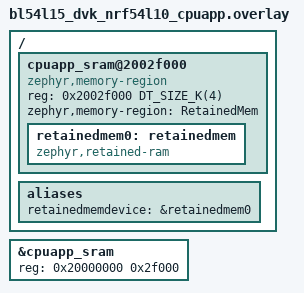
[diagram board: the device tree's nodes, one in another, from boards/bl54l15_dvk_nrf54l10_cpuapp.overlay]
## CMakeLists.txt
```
# SPDX-License-Identifier: Apache-2.0

cmake_minimum_required(VERSION 3.28.0)
find_package(Zephyr REQUIRED HINTS $ENV{ZEPHYR_BASE})
project(nrf_system_off)

target_sources(app PRIVATE src/main.c)
if(CONFIG_APP_USE_RETAINED_MEM)
  target_sources(app PRIVATE src/retained.c)
endif()
```

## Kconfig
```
# Copyright (c) 2021 Nordic Semiconductor ASA
# SPDX-License-Identifier: Apache-2.0

mainmenu "Nordic SYSTEM_OFF demo"

config APP_USE_RETAINED_MEM
	bool "Use state retention in system off using retained_mem driver"
	select RETAINED_MEM

config GPIO_WAKEUP_ENABLE
	bool "Use button to wake up device from system off"
	default y
	help
	  Enable system off wakeup from pressing sw0 button.

config GRTC_WAKEUP_ENABLE
	bool "Use GRTC to wake up device from system off"
	help
	  Enable system off wakeup from GRTC.

config LPCOMP_WAKEUP_ENABLE
	bool "Use COMP to wake up device from system off"
	help
	  Enable system off wakeup from analog comparator.

config SYS_CLOCK_DISABLE
	bool "Power down system clock before system off"
	help
	  System clock and GRTC will be switched off during system off.

source "Kconfig.zephyr"
```

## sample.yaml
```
sample:
  name: Low Power State Sample for nRF5x
common:
  tags: power
tests:
  sample.boards.nrf.system_off:
    integration_platforms:
      - nrf52840dk/nrf52840
    platform_allow:
      - nrf51dk/nrf51822
      - nrf52840dk/nrf52840
      - nrf52dk/nrf52832
      - nrf5340dk/nrf5340/cpuapp
      - nrf54l15dk/nrf54l05/cpuapp
      - nrf54l15dk/nrf54l10/cpuapp
      - nrf54l15dk/nrf54l15/cpuapp
      - nrf54lm20dk/nrf54lm20a/cpuapp
      - nrf54lm20dk/nrf54lm20b/cpuapp
      - nrf7120dk/nrf7120/cpuapp
    harness: console
    harness_config:
      type: multi_line
      ordered: true
      regex:
        - "system off demo"
        - "Retained data not supported"
        - "Entering system off; press sw0 to restart"
  sample.boards.nrf.system_off.retained_mem:
    integration_platforms:
      - nrf52840dk/nrf52840
    platform_allow:
      - nrf52840dk/nrf52840
      - nrf52dk/nrf52832
      - nrf5340dk/nrf5340/cpuapp
      - nrf54l15dk/nrf54l05/cpuapp
      - nrf54l15dk/nrf54l10/cpuapp
      - nrf54l15dk/nrf54l15/cpuapp
      - nrf54lm20dk/nrf54lm20a/cpuapp
      - nrf54lm20dk/nrf54lm20b/cpuapp
      - nrf7120dk/nrf7120/cpuapp
    extra_configs:
      - CONFIG_APP_USE_RETAINED_MEM=y
    harness: console
    harness_config:
      type: multi_line
      ordered: true
      regex:
        - "system off demo"
        - "Retained data: valid"
        - "Boot count: 1"
        - "Off count: 0"
        - "Active Ticks:"
        - "Entering system off; press sw0 to restart"
  sample.boards.nrf.system_off.grtc_off:
    platform_allow:
      - nrf54l15dk/nrf54l05/cpuapp
      - nrf54l15dk/nrf54l10/cpuapp
      - nrf54l15dk/nrf54l15/cpuapp
      - nrf54lm20dk/nrf54lm20a/cpuapp
      - nrf54lm20dk/nrf54lm20b/cpuapp
      - nrf7120dk/nrf7120/cpuapp
    extra_configs:
      - CONFIG_SYS_CLOCK_DISABLE=y
    harness: console
    harness_config:
      type: multi_line
      ordered: true
      regex:
        - "system off demo"
        - "Retained data not supported"
        - "System clock will be disabled"
        - "Entering system off; press sw0 to restart"
  sample.boards.nrf.system_off.retained_mem.grtc_off:
    platform_allow:
      - nrf54l15dk/nrf54l05/cpuapp
      - nrf54l15dk/nrf54l10/cpuapp
      - nrf54l15dk/nrf54l15/cpuapp
      - nrf54lm20dk/nrf54lm20a/cpuapp
      - nrf54lm20dk/nrf54lm20b/cpuapp
      - nrf7120dk/nrf7120/cpuapp
    extra_configs:
      - CONFIG_APP_USE_RETAINED_MEM=y
      - CONFIG_SYS_CLOCK_DISABLE=y
    harness: console
    harness_config:
      type: multi_line
      ordered: true
      regex:
        - "system off demo"
        - "Retained data: valid"
        - "Boot count: 1"
        - "Off count: 0"
        - "Active Ticks:"
        - "System clock will be disabled"
        - "Entering system off; press sw0 to restart"
  sample.boards.nrf.system_off.grtc_wakeup:
    platform_allow:
      - nrf54l15dk/nrf54l05/cpuapp
      - nrf54l15dk/nrf54l10/cpuapp
      - nrf54l15dk/nrf54l15/cpuapp
      - nrf54lm20dk/nrf54lm20a/cpuapp
      - nrf54lm20dk/nrf54lm20b/cpuapp
      - nrf7120dk/nrf7120/cpuapp
    extra_configs:
      - CONFIG_GRTC_WAKEUP_ENABLE=y
      - CONFIG_GPIO_WAKEUP_ENABLE=n
    harness: console
    harness_config:
      type: multi_line
      ordered: true
      regex:
        - "system off demo"
        - "Retained data not supported"
        - "Entering system off; wait 2 seconds to restart"
        - "system off demo"
        - "Retained data not supported"
        - "Entering system off; wait 2 seconds to restart"
        - "system off demo"
        - "Wakeup from System OFF by GRTC."
        - "Retained data not supported"
        - "Entering system off; wait 2 seconds to restart"
  sample.boards.nrf.system_off.retained_mem.grtc_wakeup:
    platform_allow:
      - nrf54l15dk/nrf54l05/cpuapp
      - nrf54l15dk/nrf54l10/cpuapp
      - nrf54l15dk/nrf54l15/cpuapp
      - nrf54lm20dk/nrf54lm20a/cpuapp
      - nrf54lm20dk/nrf54lm20b/cpuapp
      - nrf7120dk/nrf7120/cpuapp
    extra_configs:
      - CONFIG_APP_USE_RETAINED_MEM=y
      - CONFIG_GRTC_WAKEUP_ENABLE=y
      - CONFIG_GPIO_WAKEUP_ENABLE=n
    harness: console
    harness_config:
      type: multi_line
      ordered: true
      regex:
        - "system off demo"
        - "Retained data: valid"
        - "Boot count: 1"
        - "Off count: 0"
        - "Active Ticks:"
        - "Entering system off; wait 2 seconds to restart"
        - "system off demo"
        - "Retained data: valid"
        - "Boot count: 2"
        - "Off count: 1"
        - "Active Ticks:"
        - "Entering system off; wait 2 seconds to restart"
        - "Wakeup from System OFF by GRTC."
  sample.boards.nrf.system_off.lpcomp_wakeup:
    extra_args: DTC_OVERLAY_FILE="boards/nrf54l15dk_nrf54l15_cpuapp_comparator.overlay"
    platform_allow:
      - nrf54l15dk/nrf54l15/cpuapp
    extra_configs:
      - CONFIG_LPCOMP_WAKEUP_ENABLE=y
      - CONFIG_GPIO_WAKEUP_ENABLE=n
      - CONFIG_COMPARATOR=y
    harness: console
    harness_config:
      type: multi_line
      ordered: true
      regex:
        - "system off demo"
        - "Retained data not supported"
        - "Entering system off; change signal level at comparator input to restart"
  sample.boards.nrf.system_off.retained_mem.lpcomp_wakeup:
    extra_args:
      - "DTC_OVERLAY_FILE=
         boards/nrf54l15dk_nrf54l15_cpuapp_comparator.overlay;
         boards/nrf54l15dk_nrf54l15_cpuapp.overlay"
    platform_allow:
      - nrf54l15dk/nrf54l15/cpuapp
    extra_configs:
      - CONFIG_APP_USE_RETAINED_MEM=y
      - CONFIG_GPIO_WAKEUP_ENABLE=n
      - CONFIG_LPCOMP_WAKEUP_ENABLE=y
      - CONFIG_RETAINED_MEM=y
      - CONFIG_COMPARATOR=y
    harness: console
    harness_config:
      type: multi_line
      ordered: true
      regex:
        - "system off demo"
        - "Retained data: valid"
        - "Boot count: 1"
        - "Off count: 0"
        - "Active Ticks:"
        - "Entering system off; change signal level at comparator input to restart"
```

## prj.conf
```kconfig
CONFIG_PM_DEVICE=y
CONFIG_GPIO=y
CONFIG_CRC=y
CONFIG_POWEROFF=y
CONFIG_HWINFO=y
```

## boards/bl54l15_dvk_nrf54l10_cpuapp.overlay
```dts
/*
 * SPDX-License-Identifier: Apache-2.0
 *
 * Copyright (c) 2024 Nordic Semiconductor ASA
 * Copyright (c) 2025 Ezurio LLC
 */

/ {
	cpuapp_sram@2002f000 {
		compatible = "zephyr,memory-region", "mmio-sram";
		reg = <0x2002f000 DT_SIZE_K(4)>;
		zephyr,memory-region = "RetainedMem";
		status = "okay";

		retainedmem0: retainedmem {
			compatible = "zephyr,retained-ram";
			status = "okay";
		};
	};

	aliases {
		retainedmemdevice = &retainedmem0;
	};
};

&cpuapp_sram {
	/* Shrink SRAM size to avoid overlap with retained memory region:
	 * 192 - 4 = 188KB = 0x2f000
	 */
	reg = <0x20000000 0x2f000>;
	ranges = <0x0 0x20000000 0x2f000>;
};
```

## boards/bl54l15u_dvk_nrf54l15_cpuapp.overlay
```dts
/*
 * SPDX-License-Identifier: Apache-2.0
 *
 * Copyright (c) 2024 Nordic Semiconductor ASA
 * Copyright (c) 2025 Ezurio LLC
 */

/ {
	cpuapp_sram@2002e000 {
		compatible = "zephyr,memory-region", "mmio-sram";
		reg = <0x2002e000 DT_SIZE_K(4)>;
		zephyr,memory-region = "RetainedMem";
		status = "okay";

		retainedmem0: retainedmem {
			compatible = "zephyr,retained-ram";
			status = "okay";
		};
	};

	aliases {
		retainedmemdevice = &retainedmem0;
	};
};

&cpuapp_sram {
	/* Shrink SRAM size to avoid overlap with retained memory region */
	reg = <0x20000000 DT_SIZE_K(184)>;
	ranges = <0x0 0x20000000 0x2e000>;
};
```

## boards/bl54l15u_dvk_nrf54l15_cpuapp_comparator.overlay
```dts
/*
 * SPDX-License-Identifier: Apache-2.0
 *
 * Copyright (c) 2024 Nordic Semiconductor ASA
 * Copyright (c) 2025 Ezurio LLC
 */

&comp {
	compatible = "nordic,nrf-lpcomp";
	psel = "AIN4";
	refsel = "VDD_4_8";
	status = "okay";
};
```

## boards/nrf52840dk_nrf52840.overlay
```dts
/ {
	aliases {
		retainedmemdevice = &retainedmem0;
	};

	sram0@2003f000 {
		compatible = "zephyr,memory-region", "mmio-sram";
		reg = <0x2003f000 DT_SIZE_K(4)>;
		zephyr,memory-region = "RetainedMem";
		status = "okay";

		retainedmem0: retainedmem {
			compatible = "zephyr,retained-ram";
			status = "okay";
		};
	};
};

&sram0 {
	/* Shrink SRAM size to avoid overlap with retained memory region */
	reg = <0x20000000 DT_SIZE_K(252)>;
};
```

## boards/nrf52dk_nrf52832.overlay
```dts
/ {
	aliases {
		retainedmemdevice = &retainedmem0;
	};

	sram0@20007000 {
		compatible = "zephyr,memory-region", "mmio-sram";
		reg = <0x20007000 DT_SIZE_K(4)>;
		zephyr,memory-region = "RetainedMem";
		status = "okay";

		retainedmem0: retainedmem {
			compatible = "zephyr,retained-ram";
			status = "okay";
		};
	};
};

&sram0 {
	/* Shrink SRAM size to avoid overlap with retained memory region */
	reg = <0x20000000 DT_SIZE_K(28)>;
};
```

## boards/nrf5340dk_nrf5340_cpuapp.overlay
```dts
/ {
	aliases {
		retainedmemdevice = &retainedmem0;
	};

	sram0_image@2006f000 {
		compatible = "zephyr,memory-region", "mmio-sram";
		reg = <0x2006f000 DT_SIZE_K(4)>;
		zephyr,memory-region = "RetainedMem";
		status = "okay";

		retainedmem0: retainedmem {
			compatible = "zephyr,retained-ram";
			status = "okay";
		};
	};
};

&sram0_image {
	/* Shrink SRAM size to avoid overlap with retained memory region */
	reg = <0x20000000 DT_SIZE_K(444)>;
};
```

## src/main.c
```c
/*
 * Copyright (c) 2019 Nordic Semiconductor ASA
 *
 * SPDX-License-Identifier: Apache-2.0
 */

#include "retained.h"

#include <inttypes.h>
#include <stdio.h>

#include <zephyr/device.h>
#include <zephyr/drivers/gpio.h>
#include <zephyr/drivers/hwinfo.h>
#include <zephyr/drivers/comparator.h>
#include <zephyr/kernel.h>
#include <zephyr/pm/device.h>
#include <zephyr/sys/poweroff.h>
#include <zephyr/sys/util.h>
#include <zephyr/drivers/timer/system_timer.h>

#define NON_WAKEUP_RESET_REASON (RESET_PIN | RESET_SOFTWARE | RESET_POR | RESET_DEBUG)

#if defined(CONFIG_GRTC_WAKEUP_ENABLE)
#include <zephyr/drivers/timer/nrf_grtc_timer.h>
#define DEEP_SLEEP_TIME_S 2
#endif
#if defined(CONFIG_GPIO_WAKEUP_ENABLE)
static const struct gpio_dt_spec sw0 = GPIO_DT_SPEC_GET(DT_ALIAS(sw0), gpios);
#endif
#if defined(CONFIG_LPCOMP_WAKEUP_ENABLE)
static const struct device *comp_dev = DEVICE_DT_GET(DT_NODELABEL(comp));
#endif

int print_reset_cause(uint32_t reset_cause)
{
	int32_t ret;
	uint32_t supported;

	ret = hwinfo_get_supported_reset_cause((uint32_t *) &supported);

	if (ret || !(reset_cause & supported)) {
		return -ENOTSUP;
	}

	if (reset_cause & RESET_DEBUG) {
		printf("Reset by debugger.\n");
	} else if (reset_cause & RESET_CLOCK) {
		printf("Wakeup from System OFF by GRTC.\n");
	} else if (reset_cause & RESET_LOW_POWER_WAKE) {
		printf("Wakeup from System OFF by GPIO.\n");
	} else  {
		printf("Other wake up cause 0x%08X.\n", reset_cause);
	}

	return 0;
}

int main(void)
{
	int rc;
	uint32_t reset_cause;
	const struct device *const cons = DEVICE_DT_GET(DT_CHOSEN(zephyr_console));

	if (!device_is_ready(cons)) {
		printf("%s: device not ready.\n", cons->name);
		return 0;
	}

	printf("\n%s system off demo\n", CONFIG_BOARD);
	hwinfo_get_reset_cause(&reset_cause);
	rc = print_reset_cause(reset_cause);

	if (rc < 0) {
		printf("Reset cause not supported.\n");
		return 0;
	}

	if (IS_ENABLED(CONFIG_APP_USE_RETAINED_MEM)) {
		bool retained_ok = retained_validate();

		if (reset_cause & NON_WAKEUP_RESET_REASON) {
			retained.boots = 0;
			retained.off_count = 0;
			retained.uptime_sum = 0;
			retained.uptime_latest = 0;
			retained_ok = true;
		}
		/* Increment for this boot attempt and update. */
		retained.boots += 1;
		retained_update();

		printf("Retained data: %s\n", retained_ok ? "valid" : "INVALID");
		printf("Boot count: %u\n", retained.boots);
		printf("Off count: %u\n", retained.off_count);
		printf("Active Ticks: %" PRIu64 "\n", retained.uptime_sum);
	} else {
		printf("Retained data not supported\n");
	}

#if defined(CONFIG_SYS_CLOCK_DISABLE)
	printf("System clock will be disabled\n");
#endif
#if defined(CONFIG_GRTC_WAKEUP_ENABLE)
	int err = z_nrf_grtc_wakeup_prepare(DEEP_SLEEP_TIME_S * USEC_PER_SEC);

	if (err < 0) {
		printk("Unable to prepare GRTC as a wake up source (err = %d).\n", err);
		return 0;
	} else {
		printk("Entering system off; wait %u seconds to restart\n", DEEP_SLEEP_TIME_S);
	}
#endif
#if defined(CONFIG_GPIO_WAKEUP_ENABLE)
	/* configure sw0 as input, interrupt as level active to allow wake-up */
	rc = gpio_pin_configure_dt(&sw0, GPIO_INPUT);
	if (rc < 0) {
		printf("Could not configure sw0 GPIO (%d)\n", rc);
		return 0;
	}

	rc = gpio_pin_interrupt_configure_dt(&sw0, GPIO_INT_LEVEL_ACTIVE);
	if (rc < 0) {
		printf("Could not configure sw0 GPIO interrupt (%d)\n", rc);
		return 0;
	}

	printf("Entering system off; press sw0 to restart\n");
#endif
#if defined(CONFIG_LPCOMP_WAKEUP_ENABLE)
	comparator_set_trigger(comp_dev, COMPARATOR_TRIGGER_BOTH_EDGES);
	comparator_trigger_is_pending(comp_dev);
	printf("Entering system off; change signal level at comparator input to restart\n");
#endif

	rc = pm_device_action_run(cons, PM_DEVICE_ACTION_SUSPEND);
	if (rc < 0) {
		printf("Could not suspend console (%d)\n", rc);
		return 0;
	}

	if (IS_ENABLED(CONFIG_APP_USE_RETAINED_MEM)) {
		/* Update the retained state */
		retained.off_count += 1;
		retained_update();
	}

	hwinfo_clear_reset_cause();
#if defined(CONFIG_SYS_CLOCK_DISABLE)
	sys_clock_disable();
#endif
	sys_poweroff();

	return 0;
}
```

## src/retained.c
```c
/*
 * Copyright (c) 2021 Nordic Semiconductor ASA
 *
 * SPDX-License-Identifier: Apache-2.0
 */

#include "retained.h"

#include <stdint.h>
#include <string.h>

#include <zephyr/kernel.h>
#include <zephyr/devicetree.h>
#include <zephyr/drivers/retained_mem.h>
#include <zephyr/sys/byteorder.h>
#include <zephyr/sys/crc.h>

#if DT_NODE_HAS_STATUS_OKAY(DT_ALIAS(retainedmemdevice))
const static struct device *retained_mem_device = DEVICE_DT_GET(DT_ALIAS(retainedmemdevice));
#else
#error "retained_mem region not defined"
#endif

struct retained_data retained;

#define RETAINED_CRC_OFFSET offsetof(struct retained_data, crc)
#define RETAINED_CHECKED_SIZE (RETAINED_CRC_OFFSET + sizeof(retained.crc))

bool retained_validate(void)
{
	int rc;

	rc = retained_mem_read(retained_mem_device, 0, (uint8_t *)&retained, sizeof(retained));
	__ASSERT_NO_MSG(rc == 0);

	/* The residue of a CRC is what you get from the CRC over the
	 * message catenated with its CRC.  This is the post-final-xor
	 * residue for CRC-32 (CRC-32/ISO-HDLC) which Zephyr calls
	 * crc32_ieee.
	 */
	const uint32_t residue = 0x2144df1c;
	uint32_t crc = crc32_ieee((const uint8_t *)&retained,
				  RETAINED_CHECKED_SIZE);
	bool valid = (crc == residue);

	/* If the CRC isn't valid, reset the retained data. */
	if (!valid) {
		memset(&retained, 0, sizeof(retained));
	}

	/* Reset to accrue runtime from this session. */
	retained.uptime_latest = 0;

	return valid;
}

void retained_update(void)
{
	int rc;

	uint64_t now = k_uptime_ticks();

	retained.uptime_sum += (now - retained.uptime_latest);
	retained.uptime_latest = now;

	uint32_t crc = crc32_ieee((const uint8_t *)&retained,
				  RETAINED_CRC_OFFSET);

	retained.crc = sys_cpu_to_le32(crc);

	rc = retained_mem_write(retained_mem_device, 0, (uint8_t *)&retained, sizeof(retained));
	__ASSERT_NO_MSG(rc == 0);
}
```
